# ADIv5 register map
File version: 1.0
Dummy SVD file with made up addressing that describes the structure of selected ADIv5 registers
Registers are 32-bit, read-write, no defined reset value unless marked. A register's access mark holds for its fields unless they carry their own. Offsets are from the block's base; lines under a group give offsets from that group; [hi:lo] are bit positions; {n}, {i} and the like mark numbered series; 'fields as' and 'values as' point back to an identical list; <NAME> marks a mode.

## Memory map
0xFFFFFFFF00000000 AP

## AP
Base 0xFFFFFFFF00000000
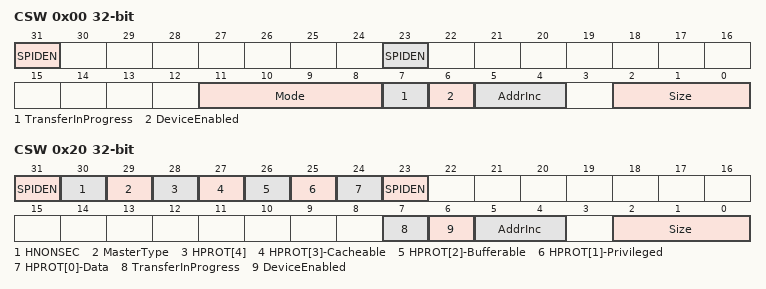
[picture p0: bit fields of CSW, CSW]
0x00 CSW — Control/Status Word register (generic)
  [31] SPIDEN
    0=Disable; 1=Enable
  [23] SPIDEN
    0=Disable; 1=Enable
  [11:8] Mode
    0=Basic; 1=Barrier Support Enabled
  [7] TransferInProgress — Halt DMA Operations
    0=Idle; 1=InProgress
  [6] DeviceEnabled
    0=Disable; 1=Enable
  [5:4] AddrInc
    0=Disabled; 1=Single; 2=Packed
  [2:0] Size
    0=Byte; 1=Halfword; 2=Word; 3=Doubleword; 4=Bits128; 5=Bits256
0x20 CSW (AmbaAhb3) — Control/Status Word register (AmbaAhb3)
  [31] SPIDEN
    0=Disable; 1=Enable
  [30] HNONSEC
  [29] MasterType
  [28] HPROT[4]
  [27] HPROT[3]-Cacheable
  [26] HPROT[2]-Bufferable
  [25] HPROT[1]-Privileged
  [24] HPROT[0]-Data
  [23] SPIDEN
    0=Disable; 1=Enable
  [7] TransferInProgress — Halt DMA Operations
    0=Idle; 1=InProgress
  [6] DeviceEnabled
    0=Disable; 1=Enable
  [5:4] AddrInc
    0=Disabled; 1=Single; 2=Packed
  [2:0] Size
    values as Size
